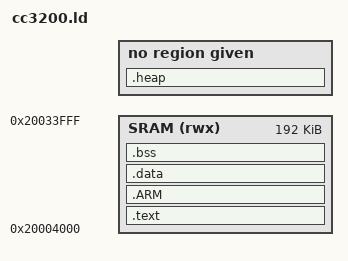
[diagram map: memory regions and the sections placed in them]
/******************************************************************************
*
*   copyright (c) 2013 texas instruments incorporated
*
*   All rights reserved. Property of Texas Instruments Incorporated.
*   Restricted rights to use, duplicate or disclose this code are
*   granted through contract.
*
*   The program may not be used without the written permission of
*   Texas Instruments Incorporated or against the terms and conditions
*   stipulated in the agreement under which this program has been supplied,
*   and under no circumstances can it be used with non-TI connectivity device.
*
******************************************************************************/

HEAP_SIZE = 0x00010000;

MEMORY
{
    SRAM (rwx) : ORIGIN = 0x20004000, LENGTH = 0x00030000
}

SECTIONS
{
    .text :
    {
        _text = .;
        KEEP(*(.intvecs))
        *(.text*)
        *(.rodata*)
        *(.ARM.extab* .gnu.linkonce.armextab.*)
        
        /* ---ENERGIA C++ Linking Specific-- */

        . = ALIGN(4);
        KEEP(*(.init))
        . = ALIGN(4);
        __preinit_array_start = .;
        KEEP (*(SORT(.preinit_array*)))
        KEEP (*(.preinit_array))
        __preinit_array_end = .;

        . = ALIGN(4);
        __init_array_start = .;
        KEEP (*(SORT(.init_array.*)))
        KEEP (*(.init_array))
        __init_array_end = .;

        . = ALIGN(4);
        KEEP(*(.fini))

        . = ALIGN(4);
        __fini_array_start = .;
        KEEP (*(.fini_array))
        KEEP (*(SORT(.fini_array.*)))
        __fini_array_end = .;

        /* ---end ENERGIA C++ Linking Specific-- */

        . = ALIGN(8);
        _etext = .;
    } > SRAM

    PROVIDE_HIDDEN (__exidx_start = .);
    .ARM : {
    __exidx_start = .;
      *(.ARM.exidx*)
      __exidx_end = .;
    } > SRAM

    __init_data = .;

    .data : AT(__init_data)
    {
        _data = .;
        *(.data*)
	. = ALIGN (8);
        _edata = .;
    } > SRAM

    .bss :
    {
        _bss = .;
        *(.bss*)
        *(COMMON)
        _ebss = .;
    } > SRAM

    .heap :
    {
	_heap = .;
	. = . + HEAP_SIZE;
	. = ALIGN(8);
	_eheap = .;

    }
}

PROVIDE(end = _end);

